# EPWM_EPWM_23000000h register map
Vendor: Texas Instruments
Peripheral module from a debugger description file (folder AM275x).
Registers are 16-bit, read-write, reset 0x0 unless marked. A register's access mark holds for its fields unless they carry their own. Offsets are as the file gives them; lines under a group give offsets from that group; [hi:lo] are bit positions; {n}, {i} and the like mark numbered series; 'fields as' and 'values as' point back to an identical list; <NAME> marks a mode.

## epwm
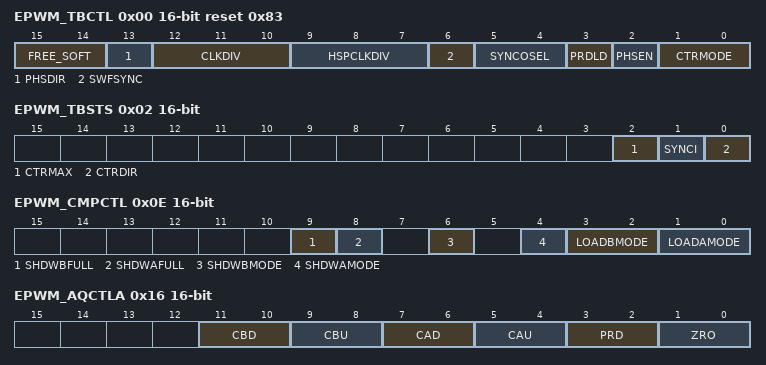
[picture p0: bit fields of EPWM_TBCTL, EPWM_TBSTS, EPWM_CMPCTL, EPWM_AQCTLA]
0x00 EPWM_TBCTL reset 0x83 — Time-Base Control Register
  [15:14] FREE_SOFT — Emulation Mode Bits These bits select the behavior of the ePWM time-base counter during emulation events: 0h Stop after the next time-base counter increment or decrement1h Stop when counter completes a whole cycle (a) Up-count mode: stop when the time-base counter = period (EPWM_TBCNT[15-0] TBCNT = EPWM_TBPRD[15-0] TBPRD). (b) Down-count mode: stop when the time-base counter = 0000 (EPWM_TBCNT[15-0] TBCNT = 0000h)2h Free run3h Free run
  [13] PHSDIR — Phase Direction Bit This bit is only used when the time-base counter is configured in the up-down-count mode The PHSDIR bit indicates the direction the time-base counter [TBCNT] will count after a synchronization event occurs and a new phase value is loaded from the phase [TBPHS] register This is irrespective of the direction of the counter before the synchronization event In the up-count and down-count modes this bit is ignored 0h Count down after the synchronization event1h Count up after the synchronization event
  [12:10] CLKDIV — Time-base Clock Prescale Bits These bits determine part of the time-base clock prescale value TBCLK = SYSCLKOUT/[HSPCLKDIV - CLKDIV] 0h /1 (default on reset)1h /22h /43h /84h /165h /326h /647h /128
  [9:7] HSPCLKDIV — High-Speed Time-base Clock Prescale Bits These bits determine part of the time-base clock prescale value TBCLK = SYSCLKOUT/[HSPCLKDIV - CLKDIV] This divisor emulates the HSPCLK in the TMS320x281x system as used on the Event Manager [EV] peripheral 0h /11h /2 (default on reset)2h /43h /64h /85h /106h /127h /14
  [6] SWFSYNC — Software Forced Synchronization Pulse 0h Writing a 0h1h Writing a 1h
  [5:4] SYNCOSEL — Synchronization Output Select These bits select the source of the EPWMxSYNCO signal 0h EPWMxSYNC1h TBCNT = 0: Time-base counter equal to zero (EPWM_TBCNT[15-0] TBCNT = 0000h)2h TBCNT = CMPB: Time-base counter equal to counter-compare B (EPWM_TBCNT[15-0] TBCNT = EPWM_CMPB[15-0] CMPB)3h Disable EPWMxSYNCO signal
  [3] PRDLD — Active Period Register Load From Shadow Register Select 0h The period register (EPWM_TBPRD) is loaded from its shadow register when the time-base counter, EPWM_TBCNT[15-0] TBCNT, is equal to zero. A write or read to the EPWM_TBPRD register accesses the shadow register.1h Load the EPWM_TBPRD register immediately without using a shadow register. A write or read to the EPWM_TBPRD register directly accesses the active register.
  [2] PHSEN — Counter Register Load From Phase Register Enable 0h Do not load the time-base counter (EPWM_TBCNT) from the time-base phase register (EPWM_TBPHS)1h Load the time-base counter with the phase register when an EPWMxSYNCI input signal occurs or when a software synchronization is forced by the SWFSYNC bit.
  [1:0] CTRMODE — Counter Mode The time-base counter mode is normally configured once and not changed during normal operation If you change the mode of the counter, the change will take effect at the next TBCLK edge and the current counter value shall increment or decrement from the value before the mode change These bits set the time-base counter mode of operation as follows: 0h Up-count mode1h Down-count mode2h Up-down-count mode3h Stop-freeze counter operation (default on reset)
0x02 EPWM_TBSTS access not given — Time-Base Status Register
  [2] CTRMAX — Time-Base Counter Max Latched Status Bit 0h Reading a 0h1h Reading a 1h (access R/W1TC)
  [1] SYNCI — Input Synchronization Latched Status Bit 0h Writing a 0h1h Reading a 1h (access R/W1TC)
  [0] CTRDIR ro — Time-Base Counter Direction Status Bit At reset, the counter is frozen, therefore, this bit has no meaning To make this bit meaningful, you must first set the appropriate mode via TBCTL[CTRMODE] 0h Time-Base Counter is currently counting down1h Time-Base Counter is currently counting up
0x04 EPWM_TBPHSHR — Time Base Phase High Resolution Register
  [15:8] TBPHSH — Time-base phase high-resolution bits
0x06 EPWM_TBPHS — Time Base Phase Register. This register is only available on ePWM instances that include the high-resolution PWM (HRPWM) extension, otherwise, this location is reserved.
  [15:0] TBPHS — These bits set time-base counter phase of the selected ePWM relative to the time-base that is supplying the synchronization input signal [a] If TBCTL[PHSEN] = 0, then the synchronization event is ignored and the time-base counter is not loaded with the phase [b] If TBCTL[PHSEN] = 1, then the time-base counter [TBCNT] will be loaded with the phase [TBPHS] when a synchronization event occurs The synchronization event can be initiated by the input synchronization signal [EPWMxSYNCI] or by a software forced synchronization
0x08 EPWM_TBCNT — Time Base Counter Register
  [15:0] TBCNT — Reading these bits gives the current time-base counter value Writing to these bits sets the current time-base counter value The update happens as soon as the write occurs The write is NOT synchronized to the time-base clock [TBCLK] and the register is not shadowed
0x0A EPWM_TBPRD — Time Base Period Register
  [15:0] TBPRD — These bits determine the period of the time-base counter This sets the PWM frequency Shadowing of this register is enabled and disabled by the TBCTL[PRDLD] bit By default this register is shadowed [a] If TBCTL[PRDLD] = 0, then the shadow is enabled and any write or read will automatically go to the shadow register In this case, the active register will be loaded from the shadow register when the time-base counter equals zero [b] If TBCTL[PRDLD] = 1, then the shadow is disabled and any write or read will go directly to the active register, that is the register actively controlling the hardware [c] The active and shadow registers share the same memory map address
0x0E EPWM_CMPCTL access per field — Counter Compare Control Register
  [9] SHDWBFULL ro — Counter-compare B [CMPB] Shadow Register Full Status Flag This bit self clears once a load-strobe occurs 0h CMPB shadow FIFO not full yet1h Indicates the CMPB shadow FIFO is full. A CPU write will overwrite current shadow value.
  [8] SHDWAFULL ro — Counter-compare A [CMPA] Shadow Register Full Status Flag The flag bit is set when a 32 bit write to CMPA:CMPAHR register or a 16 bit write to CMPA register is made A 16 bit write to CMPAHR register will not affect the flag This bit self clears once a load-strobe occurs 0h CMPA shadow FIFO not full yet1h Indicates the CMPA shadow FIFO is full, a CPU write will overwrite the current shadow value
  [6] SHDWBMODE rw — Counter-compare B [CMPB] Register Operating Mode 0h Shadow mode. Operates as a double buffer. All writes via the CPU access the shadow register.1h Immediate mode. Only the active compare B register is used. All writes and reads directly access the active register for immediate compare action.
  [4] SHDWAMODE rw — Counter-compare A [CMPA] Register Operating Mode 0h Shadow mode. Operates as a double buffer. All writes via the CPU access the shadow register.1h Immediate mode. Only the active compare register is used. All writes and reads directly access the active register for immediate compare action.
  [3:2] LOADBMODE rw — Active Counter-Compare B [CMPB] Load From Shadow Select Mode This bit has no effect in immediate mode [CMPCTL[SHDWBMODE] = 1] 0h Load on EPWM_TBCNT[15-0] TBCNT =0h Time-base counter equal to zero (EPWM_TBCNT[15-0] TBCNT= 0000h)1h Load on EPWM_TBCNT[15-0] TBCNT = EPWM_TBPRD[15-0] TBPRD: Time-base counter equal to period (EPWM_TBCNT[15-0] TBCNT = EPWM_TBPRD[15-0] TBPRD)2h Load on either EPWM_TBCNT[15-0] TBCNT = 0 or EPWM_TBCNT[15-0] TBCNT = EPWM_TBPRD[15-0] TBPRD3h Freeze (no loads possible)
  [1:0] LOADAMODE rw — Active Counter-Compare A [CMPA] Load From Shadow Select Mode This bit has no effect in immediate mode [CMPCTL[SHDWAMODE] = 1] 0h Load on TBCNT =0h Time-base counter equal to zero (EPWM_TBCNT[15-0] TBCNT = 0000h)1h Load on TBCNT = TBPRD: Time-base counter equal to period (EPWM_TBCNT[15-0] TBCNT= EPWM_TBPRD[15-0] TBPRD)2h Load on either EPWM_TBCNT[15-0] TBCNT = 0h3h Freeze (no loads possible)
0x10 EPWM_CMPAHR — Counter Compare A High Resolution Register. This register is only available on ePWM instances that include the high-resolution PWM (HRPWM) extension; otherwise, this location is reserved.
  [15:8] CMPAHR — Compare A High-Resolution register bits for MEP step control A minimum value of 1h is needed to enable HRPWM capabilities Valid MEP range of operation 1-255h
0x12 EPWM_CMPA — Counter Compare A Register
  [15:0] CMPA — The value in the active CMPA register is continuously compared to the time-base counter [TBCNT] When the values are equal, the counter-compare module generates a 'time-base counter equal to counter compare A' event This event is sent to the action-qualifier where it is qualified and converted it into one or more actions These actions can be applied to either the EPWMxA or the EPWMxB output depending on the configuration of the AQCTLA and AQCTLB registers The actions that can be defined in the AQCTLA and AQCTLB registers include the following [a] Do nothing the event is ignored [b] Clear: Pull the EPWMxA and/or EPWMxB signal low [c] Set: Pull the EPWMxA and/or EPWMxB signal high [d] Toggle the EPWMxA and/or EPWMxB signal Shadowing of this register is enabled and disabled by the CMPCTL[SHDWAMODE] bit By default this register is shadowed [a] If CMPCTL[SHDWAMODE] = 0, then the shadow is enabled and any write or read will automatically go to the shadow register In this case, the CMPCTL[LOADAMODE] bit field determines which event will load the active register from the shadow register [b] Before a write, the CMPCTL[SHDWAFULL] bit can be read to determine if the shadow register is currently full [c] If CMPCTL[SHDWAMODE] = 1, then the shadow register is disabled and any write or read will go directly to the active register, that is the register actively controlling the hardware [d] In either mode, the active and shadow registers share the same memory map address
0x14 EPWM_CMPB — Counter Compare B Register
  [15:0] CMPB — The value in the active CMPB register is continuously compared to the time-base counter [TBCNT] When the values are equal, the counter-compare module generates a 'time-base counter equal to counter compare B' event This event is sent to the action-qualifier where it is qualified and converted it into one or more actions These actions can be applied to either the EPWMxA or the EPWMxB output depending on the configuration of the AQCTLA and AQCTLB registers The actions that can be defined in the AQCTLA and AQCTLB registers include the following [a] Do nothing, the event is ignored [b] Clear: Pull the EPWMxA and/or EPWMxB signal low [c] Set: Pull the EPWMxA and/or EPWMxB signal high [d] Toggle the EPWMxA and/or EPWMxB signal Shadowing of this register is enabled and disabled by the CMPCTL[SHDWBMODE] bit By default this register is shadowed [a] If CMPCTL[SHDWBMODE] = 0, then the shadow is enabled and any write or read will automatically go to the shadow register In this case, the CMPCTL[LOADBMODE] bit field determines which event will load the active register from the shadow register: [b] Before a write, the CMPCTL[SHDWBFULL] bit can be read to determine if the shadow register is currently full [c] If CMPCTL[SHDWBMODE] = 1, then the shadow register is disabled and any write or read will go directly to the active register, that is the register actively controlling the hardware [d] In either mode, the active and shadow registers share the same memory map address
0x16 EPWM_AQCTLA — Action Qualifier Control Register For Output A
  [11:10] CBD — Action when the time-base counter equals the active CMPB register and the counter is decrementing 0h Do nothing (action disabled)1h Clear: force EPWMxA output low2h Set: force EPWMxA output high3h Toggle EPWMxA output: low output signal will be forced high, and a high signal will be forced low
  [9:8] CBU — Action when the counter equals the active CMPB register and the counter is incrementing 0h Do nothing (action disabled)1h Clear: force EPWMxA output low2h Set: force EPWMxA output high3h Toggle EPWMxA output: low output signal will be forced high, and a high signal will be forced low
  [7:6] CAD — Action when the counter equals the active CMPA register and the counter is decrementing 0h Do nothing (action disabled)1h Clear: force EPWMxA output low2h Set: force EPWMxA output high3h Toggle EPWMxA output: low output signal will be forced high, and a high signal will be forced low
  [5:4] CAU — Action when the counter equals the active CMPA register and the counter is incrementing 0h Do nothing (action disabled)1h Clear: force EPWMxA output low2h Set: force EPWMxA output high3h Toggle EPWMxA output: low output signal will be forced high, and a high signal will be forced low
  [3:2] PRD — Action when the counter equals the period Note: By definition, in count up-down mode when the counter equals period the direction is defined as 0 or counting down 0h Do nothing (action disabled)1h Clear: force EPWMxA output low2h Set: force EPWMxA output high3h Toggle EPWMxA output: low output signal will be forced high, and a high signal will be forced low
  [1:0] ZRO — Action when counter equals zero Note: By definition, in count up-down mode when the counter equals 0 the direction is defined as 1 or counting up 0h Do nothing (action disabled)1h Clear: force EPWMxA output low2h Set: force EPWMxA output high3h Toggle EPWMxA output: low output signal will be forced high, and a high signal will be forced low
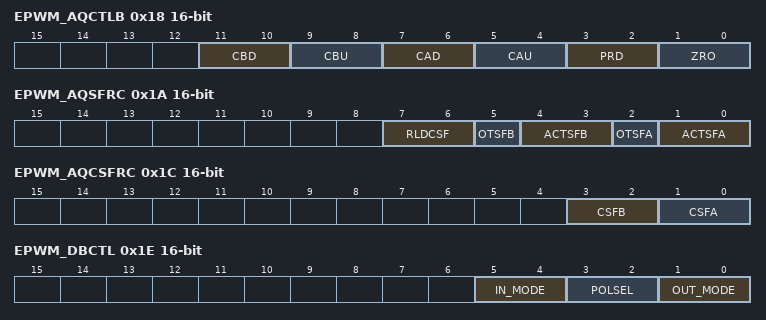
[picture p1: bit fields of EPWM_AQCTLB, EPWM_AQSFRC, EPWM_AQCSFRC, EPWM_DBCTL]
0x18 EPWM_AQCTLB — Action Qualifier Control Register For Output B
  [11:10] CBD — Action when the counter equals the active CMPB register and the counter is decrementing 0h Do nothing (action disabled)1h Clear: force EPWMxB output low2h Set: force EPWMxB output high3h Toggle EPWMxB output: low output signal will be forced high, and a high signal will be forced low
  [9:8] CBU — Action when the counter equals the active CMPB register and the counter is incrementing 0h Do nothing (action disabled)1h Clear: force EPWMxB output low2h Set: force EPWMxB output high3h Toggle EPWMxB output: low output signal will be forced high, and a high signal will be forced low
  [7:6] CAD — Action when the counter equals the active CMPA register and the counter is decrementing 0h Do nothing (action disabled)1h Clear: force EPWMxB output low2h Set: force EPWMxB output high3h Toggle EPWMxB output: low output signal will be forced high, and a high signal will be forced low
  [5:4] CAU — Action when the counter equals the active CMPA register and the counter is incrementing 0h Do nothing (action disabled)1h Clear: force EPWMxB output low2h Set: force EPWMxB output high3h Toggle EPWMxB output: low output signal will be forced high, and a high signal will be forced low
  [3:2] PRD — Action when the counter equals the period Note: By definition, in count up-down mode when the counter equals period the direction is defined as 0 or counting down 0h Do nothing (action disabled)1h Clear: force EPWMxB output low2h Set: force EPWMxB output high3h Toggle EPWMxB output: low output signal will be forced high, and a high signal will be forced low
  [1:0] ZRO — Action when counter equals zero Note: By definition, in count up-down mode when the counter equals 0 the direction is defined as 1 or counting up 0h Do nothing (action disabled)1h Clear: force EPWMxB output low2h Set: force EPWMxB output high3h Toggle EPWMxB output: low output signal will be forced high, and a high signal will be forced low
0x1A EPWM_AQSFRC access not given — Action Qualifier Software Force Register
  [7:6] RLDCSF rw — AQCSFRC Active Register Reload From Shadow Options
  [5] OTSFB — One-Time Software Forced Event on Output B 0h Writing a 0h (1h Initiates a single s/w forced event (access R/W1TC)
  [4:3] ACTSFB rw — Action when One-Time Software Force B Is invoked 0h Does nothing (action disabled)1h Clear (low)2h Set (high)3h Toggle (Low -> High, High -> Low).
  [2] OTSFA — One-Time Software Forced Event on Output A 0h Writing a 0 (zero) has no effect. Always reads back a 0. This bit is auto cleared once a write to this register is complete (that is, a forced event is initiated).1h Initiates a single software forced event. (access R/W1TC)
  [1:0] ACTSFA rw — Action When One-Time Software Force A Is Invoked 0h Does nothing (action disabled).1h Clear (low).2h Set (high).3h Toggle (Low -> High, High -> Low).
0x1C EPWM_AQCSFRC — Action Qualifier Continuous S/W Force Register
  [3:2] CSFB — Continuous Software Force on Output B In immediate mode, a continuous force takes effect on the next TBCLK edge In shadow mode, a continuous force takes effect on the next TBCLK edge after a shadow load into the active register To configure shadow mode, use AQSFRC[RLDCSF] 0h Forcing disabled, that is, has no effect1h Forces a continuous low on output B2h Forces a continuous high on output B3h Software forcing is disabled and has no effect
  [1:0] CSFA — Continuous Software Force on Output A In immediate mode, a continuous force takes effect on the next TBCLK edge In shadow mode, a continuous force takes effect on the next TBCLK edge after a shadow load into the active register 0h Forcing disabled, that is, has no effect1h Forces a continuous low on output A2h Forces a continuous high on output A3h Software forcing is disabled and has no effect
0x1E EPWM_DBCTL — Dead-Band Generator Control Register
  [5:4] IN_MODE — Dead Band Input Mode Control Bit 5 controls the S5 switch and bit 4 controls the S4 switch This allows you to select the input source to the falling-edge and rising-edge delay To produce classical dead-band waveforms, the default is EPWMxA In is the source for both falling and rising-edge delays 0h EPWMxA In (from the action-qualifier) is the source for both falling-edge and rising-edge delay.1h EPWMxB In (from the action-qualifier) is the source for rising- edge delayed signal. EPWMxA In (from the action-qualifier) is the source for falling-edge delayed signal.2h EPWMxA In (from the action-qualifier) is the source for rising- edge delayed signal. EPWMxB In (from the action-qualifier) is the source for falling-edge delayed signal.3h EPWMxB In (from the action-qualifier) is the source for both rising-edge delay and falling-edge delayed signal.
  [3:2] POLSEL — Polarity Select Control Bit 3 controls the S3 switch and bit 2 controls the S2 switch This allows you to selectively invert one of the delayed signals before it is sent out of the dead-band submodule The following descriptions correspond to classical upper/lower switch control as found in one leg of a digital motor control inverter These assume that DBCTL[OUT_MODE] = 1,1 and DBCTL[IN_MODE] = 0,0 Other enhanced modes are also possible, but not regarded as typical usage modes 0h Active high (AH) mode. Neither EPWMxA nor EPWMxB is inverted (default).1h Active low complementary (ALC) mode. EPWMxA is inverted.2h Active high complementary (AHC). EPWMxB is inverted.3h Active low (AL) mode. Both EPWMxA and EPWMxB are inverted.
  [1:0] OUT_MODE — Dead-band Output Mode Control Bit 1 controls the S1 switch and bit 0 controls the S0 switch This allows you to selectively enable or bypass the dead-band generation for the falling-edge and rising-edge delay 0h Dead-band generation is bypassed for both output signals. In this mode, both the EPWMxA and EPWMxB output signals from the action-qualifier are passed directly to the PWM-chopper submodule. In this mode, the POLSEL and IN_MODE bits have no effect.1h Disable rising-edge delay. The EPWMxA signal from the action- qualifier is passed straight through to the EPWMxA input of the PWM-chopper submodule. The falling-edge delayed signal is seen on output EPWMxB. The input signal for the delay is determined by the EPWM_DBCTL[5-4] IN_MODE bit field.2h Disable falling-edge delay. The EPWMxB signal from the action- qualifier is passed straight through to the EPWMxB input of the PWM-chopper submodule. The rising-edge delayed signal is seen on output EPWMxA. The input signal for the delay is determined by the EPWM_DBCTL[5-4] IN_MODE bit field.3h Dead-band is fully enabled for both rising- edge delay on output EPWMxA and falling- edge delay on output EPWMxB. The input signal for the delay is determined by the EPWM_DBCTL[5-4] IN_MODE bit field.
0x20 EPWM_DBRED — Dead-Band Generator Rising Edge Delay Count Register
  [9:0] DEL — Rising Edge Delay Count 10 bit counter
0x22 EPWM_DBFED — Dead-Band Generator Falling Edge Delay Count Register
  [9:0] DEL — Falling Edge Delay Count 10 bit counter
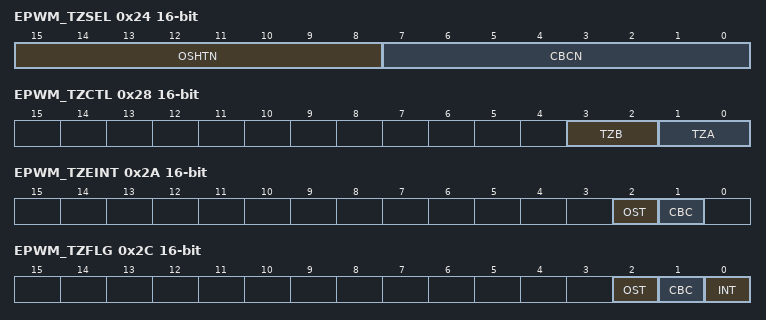
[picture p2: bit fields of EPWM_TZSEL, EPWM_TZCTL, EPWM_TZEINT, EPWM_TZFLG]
0x24 EPWM_TZSEL — Trip Zone Select Register
  [15:8] OSHTN — Trip-zone n [TZn] select One-Shot [OSHT] trip-zone enable/disable When any of the enabled pins go low, a one-shot trip event occurs for this ePWM module When the event occurs, the action defined in the TZCTL register is taken on the EPWMxA and EPWMxB outputs The one-shot trip condition remains latched until you clear the condition via the TZCLR register 0h Disable TZn as a one-shot trip source for this EPWM module1h Enable TZn as a one-shot trip source for this EPWM module
  [7:0] CBCN — Trip-zone n [TZn] select Cycle-by-Cycle [CBC] trip-zone enable/disable When any of the enabled pins go low, a cycle-by-cycle trip event occurs for this ePWM module When the event occurs, the action defined in the TZCTL register is taken on the EPWMxA and EPWMxB outputs A cycle-by-cycle trip condition is automatically cleared when the time-base counter reaches zero 0h Disable TZn as a CBC trip source for this EPWM module1h Enable TZn as a CBC trip source for this EPWM module
0x28 EPWM_TZCTL — Trip Zone Control Register
  [3:2] TZB — When a trip event occurs the following action is taken on output EPWMxB Which trip-zone pins can cause an event is defined in the TZSEL register 0h High impedance (EPWMxB = High-impedance state)1h Force EPWMxB to a high state2h Force EPWMxB to a low state3h Do nothing, no action is taken on EPWMxB.
  [1:0] TZA — When a trip event occurs the following action is taken on output EPWMxA Which trip-zone pins can cause an event is defined in the TZSEL register 0h High impedance (EPWMxA = High-impedance state)1h Force EPWMxA to a high state2h Force EPWMxA to a low state3h Do nothing, no action is taken on EPWMxA.
0x2A EPWM_TZEINT — Trip Zone Enable Interrupt Register
  [2] OST — Trip-zone One-Shot Interrupt Enable 0h Disable one-shot interrupt generation1h Enable Interrupt generation a one-shot trip event will cause a EPWMxTZINT interrupt.
  [1] CBC — Trip-zone Cycle-by-Cycle Interrupt Enable 0h Disable cycle-by-cycle interrupt generation1h Enable interrupt generation a cycle-by- cycle trip event will cause an EPWMxTZINT interrupt.
0x2C EPWM_TZFLG ro — Trip Zone Flag Register
  [2] OST — Latched Status Flag for A One-Shot Trip Event 0h No one-shot trip event has occurred1h Indicates a trip event has occurred on a pin selected as a one-shot trip source. This bit is cleared by writing the appropriate value to the EPWM_TZCLR register.
  [1] CBC — Latched Status Flag for Cycle-By-Cycle Trip Event 0h No cycle-by-cycle trip event has occurred1h Indicates a trip event has occurred on a pin selected as a cycle-by-cycle trip source. The EPWM_TZFLG[1] CBC bit will remain set until it is manually cleared by the user. If the cycle-by-cycle trip event is still present when the CBC bit is cleared, then CBC will be immediately set again. The specified condition on the pins is automatically cleared when the EPWM time-base counter reaches zero (EPWM_TBCNT[15-0] TBCNT = 0000h)
  [0] INT — Latched Trip Interrupt Status Flag 0h Indicates no interrupt has been generated1h Indicates an EPWMxTZINT interrupt was generated because of a trip condition. No further EPWMxTZINT interrupts will be generated until this flag is cleared. If the interrupt flag is cleared when either CBC or OST is set, then another interrupt pulse will be generated. Clearing all flag bits will prevent further interrupts. This bit is cleared by writing the appropriate value to the EPWM_TZCLR register.
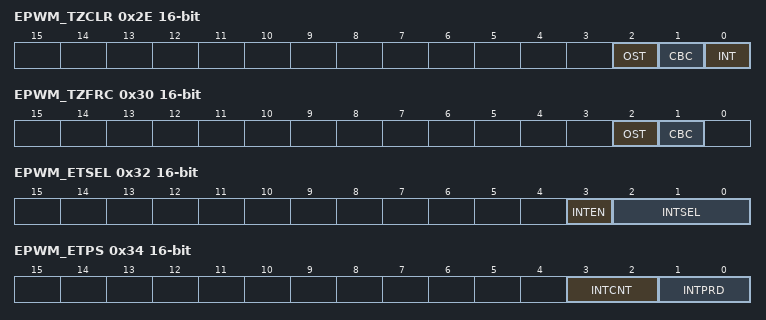
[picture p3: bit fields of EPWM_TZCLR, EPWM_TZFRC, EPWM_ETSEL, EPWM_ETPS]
0x2E EPWM_TZCLR — Trip Zone Clear Register
  [2] OST — Clear Flag for One-Shot Trip [OST] Latch 0h Has no effect. Always reads back a 0h1h Clears this Trip (set) condition
  [1] CBC — Clear Flag for Cycle-By-Cycle [CBC] Trip Latch 0h Has no effect. Always reads back a 0h1h Clears this Trip (set) condition
  [0] INT — Global Interrupt Clear Flag 0h Has no effect. Always reads back a 0h1h Clears the trip-interrupt flag for this EPWM module (EPWM_TZFLG[0] INT)
0x30 EPWM_TZFRC — Trip Zone Force Register
  [2] OST — Force a One-Shot Trip Event via Software 0h Writing of 0h1h Forces a one-shot trip event and sets the EPWM_TZFLG[2] OST bit.
  [1] CBC — Force a Cycle-by-Cycle Trip Event via Software 0h Writing of 0h1h Forces a cycle-by-cycle trip event and sets the EPWM_TZFLG[1] CBC bit.
0x32 EPWM_ETSEL — Event Trigger Selection Register
  [3] INTEN — Enable ePWM Interrupt [EPWMx_INT] Generation 0h Disable EPWMx_INT generation1h Enable EPWMx_INT generation
  [2:0] INTSEL — ePWM Interrupt [EPWMx_INT] Selection Options 0h Reserved1h Enable event time-base counter equal to zero. (EPWM_TBCNT = 0000h)2h Enable event time-base counter equal to period (EPWM_TBCNT = EPWM_TBPRD)3h Reserved4h Enable event time-base counter equal to CMPA when the timer is incrementing5h Enable event time-base counter equal to CMPA when the timer is decrementing6h Enable event time-base counter equal to CMPB when the timer is incrementing7h Enable event time-base counter equal to CMPB when the timer is decrementing
0x34 EPWM_ETPS access per field — Event Trigger Pre-Scale Register
  [3:2] INTCNT ro — ePWM Interrupt Event [EPWMx_INT] Counter Register These bits indicate how many selected ETSEL[INTSEL] events have occurred These bits are automatically cleared when an interrupt pulse is generated If interrupts are disabled, ETSEL[INT] = 0 or the interrupt flag is set, ETFLG[INT] = 1, the counter will stop counting events when it reaches the period value ETPS[INTCNT] = ETPS[INTPRD] 0h No events have occurred1h 1 event has occurred2h 2 events have occurred3h 3 events have occurred
  [1:0] INTPRD rw — ePWM Interrupt [EPWMx_INT] Period Select These bits determine how many selected ETSEL[INTSEL] events need to occur before an interrupt is generated To be generated, the interrupt must be enabled [ETSEL[INT] = 1] If the interrupt status flag is set from a previous interrupt [ETFLG[INT] = 1] then no interrupt will be generated until the flag is cleared via the ETCLR[INT] bit This allows for one interrupt to be pending while another is still being serviced Once the interrupt is generated, the ETPS[INTCNT] bits will automatically be cleared Writing a INTPRD value that is the same as the current counter value will trigger an interrupt if it is enabled and the status flag is clear Writing a INTPRD value that is less than the current counter value will result in an undefined state If a counter event occurs at the same instant as a new zero or non-zero INTPRD value is written, the counter is incremented 0h Disable the interrupt event counter. No interrupt will be generated and the EPWM_ETFRC[0] INT bit is ignored.1h Generate an interrupt on the first event INTCNT = 0b01 (first event)2h Generate interrupt on the EPWM_ETPS[3-2] INTCNT = 0b10 (second event)3h Generate interrupt on the EPWM_ETPS[3-2] INTCNT = 0b11 (third event)
0x36 EPWM_ETFLG ro — Event Trigger Flag Register
  [0] INT — Latched ePWM Interrupt [EPWMx_INT] Status Flag 0h Indicates no event occurred.1h Indicates that an EPWMx interrupt (EWPMx_INT) was generated. No further interrupts will be generated until the flag bit is cleared. Up to one interrupt can be pending while the EPWM_ETFLG[0] INT bit is still set. If an interrupt is pending, it will not be generated until after the EPWM_ETFLG[0] INT bit is cleared.
0x38 EPWM_ETCLR ro — Event Trigger Clear Register
  [0] INT — ePWM Interrupt [EPWMx_INT] Flag Clear Bit
0x3A EPWM_ETFRC ro — Event Trigger Force Register
  [0] INT — INT Force Bit The interrupt will only be generated if the event is enabled in the ETSEL register The INT flag bit will be set regardless 0h Writing a 0 has no effect. Always reads back a 0h1h Writing 1 clears the EPWM_ETFLG[0] INT flag bit and enable further interrupts pulses to be generated.
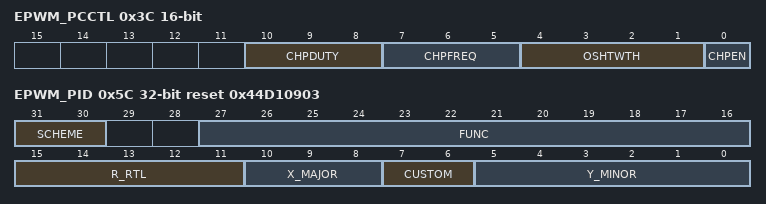
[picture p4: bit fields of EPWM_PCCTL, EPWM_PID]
0x3C EPWM_PCCTL — PWM Chopper Control Register
  [10:8] CHPDUTY — Chopping Clock Duty Cycle 0h Duty = 1/8 (12.5%)1h Duty = 2/8 (25.0%)2h Duty = 3/8 (37.5%)3h Duty = 4/8 (50.0%)4h Duty = 5/8 (62.5%)5h Duty = 6/8 (75.0%)6h Duty = 7/8 (87.5%)7h Reserved
  [7:5] CHPFREQ — Chopping Clock Frequency 0h Divide by 1 (no prescale)1h Divide by 22h Divide by 33h Divide by 44h Divide by 55h Divide by 66h Divide by 77h Divide by 8
  [4:1] OSHTWTH — One-Shot Pulse Width 0h 1 - SYSCLKOUT/8 wide1h 2 - SYSCLKOUT/8 wide2h 3 - SYSCLKOUT/8 wide3h 4 - SYSCLKOUT/8 wide3h 4 - SYSCLKOUT/8 wide
  [0] CHPEN — PWM-chopping Enable 0h Disable (bypass) PWM chopping function1h Enable chopping function
0x5C EPWM_PID 32-bit ro reset 0x44D10903 — EHRPWM Peripheral ID Register. The IP revision register is used by software to track features, bugs, and compatibility.
  [31:30] SCHEME — Used to distinguish between the old scheme and current
  [27:16] FUNC
  [15:11] R_RTL — RTL version [R], maintained by IP design owner
  [10:8] X_MAJOR — Major revision [X]
  [7:6] CUSTOM
  [5:0] Y_MINOR — Minor revision [Y]
